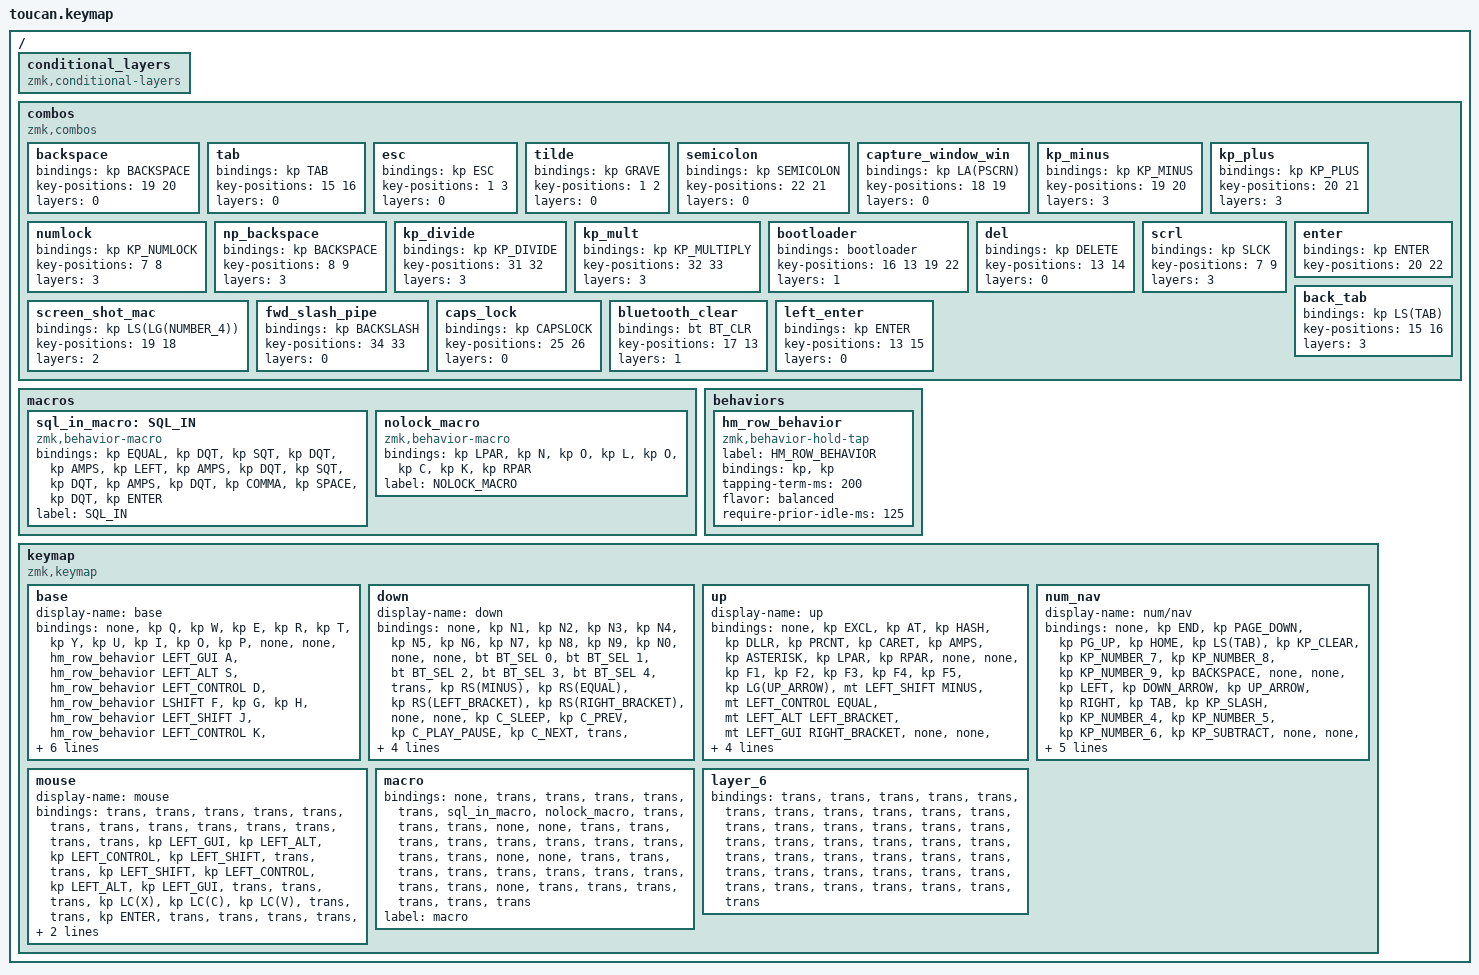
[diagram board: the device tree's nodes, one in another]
#include <behaviors.dtsi>
#include <dt-bindings/zmk/bt.h>
#include <dt-bindings/zmk/keys.h>
#include <dt-bindings/zmk/pointing.h>

#define BASE 0
#define NAV  1
#define SYM  2
#define ADJ  3

/ {
    conditional_layers { compatible = "zmk,conditional-layers"; };

    combos {
        compatible = "zmk,combos";

        backspace {
            bindings = <&kp BACKSPACE>;
            key-positions = <19 20>;
            layers = <0>;
        };

        tab {
            bindings = <&kp TAB>;
            key-positions = <15 16>;
            layers = <0>;
        };

        esc {
            bindings = <&kp ESC>;
            key-positions = <1 3>;
            layers = <0>;
        };

        tilde {
            bindings = <&kp GRAVE>;
            key-positions = <1 2>;
            layers = <0>;
        };

        semicolon {
            bindings = <&kp SEMICOLON>;
            key-positions = <22 21>;
            layers = <0>;
        };

        capture_window_win {
            bindings = <&kp LA(PSCRN)>;
            key-positions = <18 19>;
            layers = <0>;
        };

        kp_minus {
            bindings = <&kp KP_MINUS>;
            key-positions = <19 20>;
            layers = <3>;
        };

        kp_plus {
            bindings = <&kp KP_PLUS>;
            key-positions = <20 21>;
            layers = <3>;
        };

        numlock {
            bindings = <&kp KP_NUMLOCK>;
            key-positions = <7 8>;
            layers = <3>;
        };

        np_backspace {
            bindings = <&kp BACKSPACE>;
            key-positions = <8 9>;
            layers = <3>;
        };

        kp_divide {
            bindings = <&kp KP_DIVIDE>;
            key-positions = <31 32>;
            layers = <3>;
        };

        kp_mult {
            bindings = <&kp KP_MULTIPLY>;
            key-positions = <32 33>;
            layers = <3>;
        };

        bootloader {
            bindings = <&bootloader>;
            key-positions = <16 13 19 22>;
            layers = <1>;
        };

        del {
            bindings = <&kp DELETE>;
            key-positions = <13 14>;
            layers = <0>;
        };

        scrl {
            bindings = <&kp SLCK>;
            key-positions = <7 9>;
            layers = <3>;
        };

        screen_shot_mac {
            bindings = <&kp LS(LG(NUMBER_4))>;
            key-positions = <19 18>;
            layers = <2>;
        };

        fwd_slash_pipe {
            bindings = <&kp BACKSLASH>;
            key-positions = <34 33>;
            layers = <0>;
        };

        caps_lock {
            bindings = <&kp CAPSLOCK>;
            key-positions = <25 26>;
            layers = <0>;
        };

        enter {
            bindings = <&kp ENTER>;
            key-positions = <20 22>;
        };

        back_tab {
            bindings = <&kp LS(TAB)>;
            key-positions = <15 16>;
            layers = <3>;
        };

        bluetooth_clear {
            bindings = <&bt BT_CLR>;
            key-positions = <17 13>;
            layers = <1>;
        };

        left_enter {
            bindings = <&kp ENTER>;
            key-positions = <13 15>;
            layers = <0>;
        };
    };

    macros {
        sql_in_macro: SQL_IN {
            compatible = "zmk,behavior-macro";
            #binding-cells = <0>;
            bindings = <&kp EQUAL &kp DQT &kp SQT &kp DQT &kp AMPS &kp LEFT &kp AMPS &kp DQT &kp SQT &kp DQT &kp AMPS &kp DQT &kp COMMA &kp SPACE &kp DQT &kp ENTER>;
            label = "SQL_IN";
        };

        nolock_macro: nolock_macro {
            compatible = "zmk,behavior-macro";
            #binding-cells = <0>;
            bindings = <&kp LPAR &kp N &kp O &kp L &kp O &kp C &kp K &kp RPAR>;
            label = "NOLOCK_MACRO";
        };
    };

    behaviors {
        hm_row_behavior: hm_row_behavior {
            compatible = "zmk,behavior-hold-tap";
            label = "HM_ROW_BEHAVIOR";
            bindings = <&kp>, <&kp>;

            #binding-cells = <2>;
            tapping-term-ms = <200>;
            flavor = "balanced";
            require-prior-idle-ms = <125>;
        };
    };

    keymap {
        compatible = "zmk,keymap";

        base {
            display-name = "base";
            bindings = <
&none  &kp Q  &kp W  &kp E  &kp R  &kp T  &kp Y  &kp U  &kp I  &kp O  &kp P  &none  &none  &hm_row_behavior LEFT_GUI A  &hm_row_behavior LEFT_ALT S  &hm_row_behavior LEFT_CONTROL D  &hm_row_behavior LSHIFT F  &kp G  &kp H  &hm_row_behavior LEFT_SHIFT J  &hm_row_behavior LEFT_CONTROL K  &hm_row_behavior LEFT_ALT L  &hm_row_behavior LEFT_GUI SQT  &none  &none  &mt LEFT_SHIFT Z  &kp X  &kp C  &kp V  &kp B  &kp N  &kp M  &kp COMMA  &kp DOT  &mt LEFT_SHIFT FSLH  &none  &kp LGUI  &mo 1  &lt 3 SPACE  &lt 5 SPACE  &mo 2  &kp RALT
            >;
        };

        down {
            display-name = "down";
            bindings = <
&none  &kp N1  &kp N2  &kp N3  &kp N4  &kp N5  &kp N6  &kp N7  &kp N8  &kp N9  &kp N0  &none  &none  &bt BT_SEL 0  &bt BT_SEL 1  &bt BT_SEL 2  &bt BT_SEL 3  &bt BT_SEL 4  &trans  &kp RS(MINUS)  &kp RS(EQUAL)  &kp RS(LEFT_BRACKET)  &kp RS(RIGHT_BRACKET)  &none  &none  &kp C_SLEEP  &kp C_PREV  &kp C_PLAY_PAUSE  &kp C_NEXT  &trans  &kp C_BRIGHTNESS_DEC  &kp C_BRIGHTNESS_INC  &kp K_MUTE  &kp C_VOLUME_DOWN  &kp C_VOLUME_UP  &none  &kp LGUI  &trans  &trans  &kp SPACE  &trans  &kp RALT
            >;
        };

        up {
            display-name = "up";
            bindings = <
&none  &kp EXCL  &kp AT  &kp HASH  &kp DLLR  &kp PRCNT  &kp CARET  &kp AMPS  &kp ASTERISK  &kp LPAR  &kp RPAR  &none  &none  &kp F1  &kp F2  &kp F3  &kp F4  &kp F5  &kp LG(UP_ARROW)  &mt LEFT_SHIFT MINUS  &mt LEFT_CONTROL EQUAL  &mt LEFT_ALT LEFT_BRACKET  &mt LEFT_GUI RIGHT_BRACKET  &none  &none  &kp F6  &kp F7  &kp F8  &kp F9  &kp F10  &kp F11  &kp F12  &kp K_MUTE  &kp C_VOLUME_DOWN  &kp C_VOL_UP  &none  &kp LGUI  &trans  &trans  &kp SPACE  &kp LG(DOWN)  &kp RALT
            >;
        };

        num_nav {
            display-name = "num/nav";
            bindings = <
&none  &kp END  &kp PAGE_DOWN  &kp PG_UP  &kp HOME  &kp LS(TAB)  &kp KP_CLEAR  &kp KP_NUMBER_7  &kp KP_NUMBER_8  &kp KP_NUMBER_9  &kp BACKSPACE  &none  &none  &kp LEFT  &kp DOWN_ARROW  &kp UP_ARROW  &kp RIGHT  &kp TAB  &kp KP_SLASH  &kp KP_NUMBER_4  &kp KP_NUMBER_5  &kp KP_NUMBER_6  &kp KP_SUBTRACT  &none  &none  &kp LC(Z)  &kp LC(X)  &kp LC(C)  &kp LC(V)  &trans  &kp KP_MULTIPLY  &kp KP_NUMBER_1  &kp KP_NUMBER_2  &kp KP_N3  &kp KP_PLUS  &none  &kp LGUI  &mo 1  &trans  &kp KP_ENTER  &kp KP_N0  &kp KP_DOT
            >;
        };

        mouse {
            display-name = "mouse";
            bindings = <
&trans  &trans  &trans  &trans  &trans  &trans  &trans  &trans  &trans  &trans  &trans  &trans  &trans  &kp LEFT_GUI  &kp LEFT_ALT  &kp LEFT_CONTROL  &kp LEFT_SHIFT  &trans  &trans  &kp LEFT_SHIFT  &kp LEFT_CONTROL  &kp LEFT_ALT  &kp LEFT_GUI  &trans  &trans  &trans  &kp LC(X)  &kp LC(C)  &kp LC(V)  &trans  &trans  &kp ENTER  &trans  &trans  &trans  &trans  &mkp MCLK  &mkp LCLK  &mkp RCLK  &mkp LCLK  &mkp RCLK  &mkp MCLK
            >;
        };

        macro {
            bindings = <
&none  &trans  &trans  &trans  &trans  &trans  &sql_in_macro  &nolock_macro  &trans  &trans  &trans  &none  &none  &trans  &trans  &trans  &trans  &trans  &trans  &trans  &trans  &trans  &trans  &none  &none  &trans  &trans  &trans  &trans  &trans  &trans  &trans  &trans  &trans  &trans  &none  &trans  &trans  &trans  &trans  &trans  &trans
            >;

            label = "macro";
        };

        layer_6 {
            bindings = <
&trans  &trans  &trans  &trans  &trans  &trans  &trans  &trans  &trans  &trans  &trans  &trans  &trans  &trans  &trans  &trans  &trans  &trans  &trans  &trans  &trans  &trans  &trans  &trans  &trans  &trans  &trans  &trans  &trans  &trans  &trans  &trans  &trans  &trans  &trans  &trans  &trans  &trans  &trans  &trans  &trans  &trans
            >;
        };
    };
};
